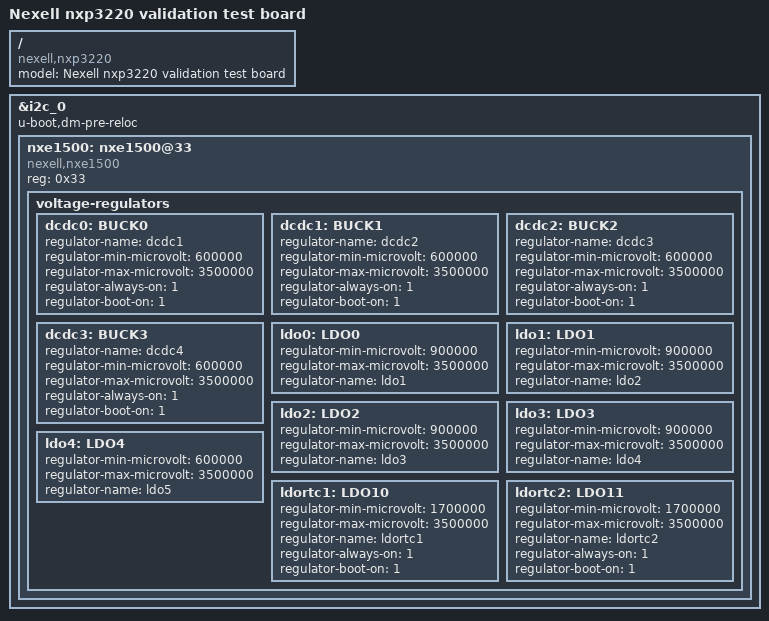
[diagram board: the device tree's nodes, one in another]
/*
 * (C) Copyright 2018 Nexell
 * JungHyun, Kim <jhkim@nexell.co.kr>
 *
 * SPDX-License-Identifier:      GPL-2.0+
 */

/dts-v1/;

#include "nxp3220-vtk-common.dtsi"
#include <dt-bindings/gpio/gpio.h>
/ {
	model = "Nexell nxp3220 validation test board";
	compatible = "nexell,nxp3220";
};

&i2c_0 {
	status = "okay";
	u-boot,dm-pre-reloc;
	#address-cells = <1>;
	#size-cells = <0>;

	nxe1500: nxe1500@33 {
		compatible = "nexell,nxe1500";
		reg = <0x33>;

		voltage-regulators {
			dcdc0: BUCK0 {
				regulator-name = "dcdc1";
				regulator-min-microvolt = <600000>;
				regulator-max-microvolt = <3500000>;
				regulator-always-on = <1>;
				regulator-boot-on = <1>;
			};

			dcdc1: BUCK1 {
				regulator-name = "dcdc2";
				regulator-min-microvolt = <600000>;
				regulator-max-microvolt = <3500000>;
				regulator-always-on = <1>;
				regulator-boot-on = <1>;
			};

			dcdc2: BUCK2 {
				regulator-name = "dcdc3";
				regulator-min-microvolt = <600000>;
				regulator-max-microvolt = <3500000>;
				regulator-always-on = <1>;
				regulator-boot-on = <1>;
			};

			dcdc3: BUCK3 {
				regulator-name = "dcdc4";
				regulator-min-microvolt = <600000>;
				regulator-max-microvolt = <3500000>;
				regulator-always-on = <1>;
				regulator-boot-on = <1>;
			};

			ldo0: LDO0 {
				regulator-min-microvolt = <900000>;
				regulator-max-microvolt = <3500000>;
				regulator-name = "ldo1";
			};

			ldo1: LDO1 {
				regulator-min-microvolt = <900000>;
				regulator-max-microvolt = <3500000>;
				regulator-name = "ldo2";
			};

			ldo2: LDO2 {
				regulator-min-microvolt = <900000>;
				regulator-max-microvolt = <3500000>;
				regulator-name = "ldo3";
			};

			ldo3: LDO3 {
				regulator-min-microvolt = <900000>;
				regulator-max-microvolt = <3500000>;
				regulator-name = "ldo4";
			};

			ldo4: LDO4 {
				regulator-min-microvolt = <600000>;
				regulator-max-microvolt = <3500000>;
				regulator-name = "ldo5";
			};

			ldortc1: LDO10 {
				regulator-min-microvolt = <1700000>;
				regulator-max-microvolt = <3500000>;
				regulator-name = "ldortc1";
				regulator-always-on = <1>;
				regulator-boot-on = <1>;
			};

			ldortc2: LDO11 {
				regulator-min-microvolt = <1700000>;
				regulator-max-microvolt = <3500000>;
				regulator-name = "ldortc2";
				regulator-always-on = <1>;
				regulator-boot-on = <1>;
			};
		}; /* voltage-regulators */
	};
};
